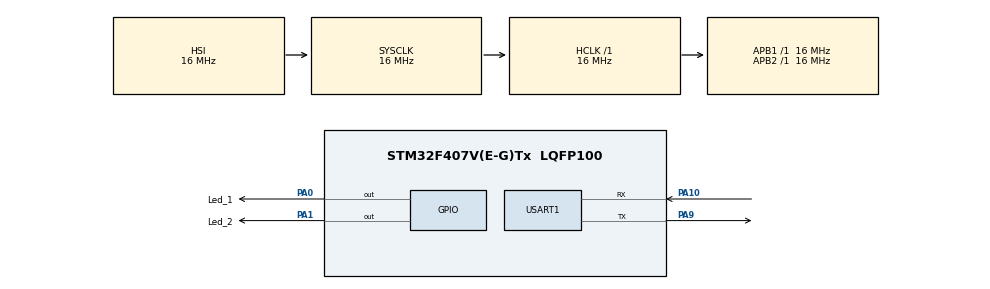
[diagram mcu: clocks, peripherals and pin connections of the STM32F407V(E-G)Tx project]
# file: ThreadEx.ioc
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FREERTOS.Tasks01=Islem1,24,128,Fonksiyon1,Default,NULL,Dynamic,NULL,NULL;Islem2,16,128,Fonksiyon2,Default,NULL,Dynamic,NULL,NULL
Mcu.Family=STM32F4
Mcu.Name=STM32F407V(E-G)Tx
Mcu.Package=LQFP100
NVIC.PriorityGroup=NVIC_PRIORITYGROUP_4
NVIC.TIM1_UP_TIM10_IRQn=true\:15\:0\:false\:false\:true\:false\:false\:true
NVIC.TimeBase=TIM1_UP_TIM10_IRQn
NVIC.TimeBaseIP=TIM1
PA0-WKUP.GPIO_Label=Led_1
PA0-WKUP.Signal=GPIO_Output
PA1.GPIO_Label=Led_2
PA1.Signal=GPIO_Output
PA10.Mode=Asynchronous
PA10.Signal=USART1_RX
PA9.Mode=Asynchronous
PA9.Signal=USART1_TX
PH0-OSC_IN.Mode=HSE-External-Oscillator
PH0-OSC_IN.Signal=RCC_OSC_IN
PH1-OSC_OUT.Mode=HSE-External-Oscillator
PH1-OSC_OUT.Signal=RCC_OSC_OUT
ProjectManager.HeapSize=0x200
ProjectManager.StackSize=0x400
ProjectManager.TargetToolchain=STM32CubeIDE
RCC.AHBFreq_Value=16000000
RCC.APB1Freq_Value=16000000
RCC.APB2Freq_Value=16000000
RCC.CortexFreq_Value=16000000
RCC.HSE_VALUE=25000000
RCC.HSI_VALUE=16000000
RCC.LSE_VALUE=32768
RCC.SYSCLKFreq_VALUE=16000000
RCC.VCOOutputFreq_Value=192000000
USART1.VirtualMode=VM_ASYNC
VP_FREERTOS_VS_CMSIS_V2.Mode=CMSIS_V2
VP_SYS_VS_tim1.Mode=TIM1
board=custom

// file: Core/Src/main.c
/* USER CODE BEGIN Header */
/**
  ******************************************************************************
  * @file           : main.c
  * @brief          : Main program body
  ******************************************************************************
  * @attention
  *
  * Copyright (c) 2023 STMicroelectronics.
  * All rights reserved.
  *
  * This software is licensed under terms that can be found in the LICENSE file
  * in the root directory of this software component.
  * If no LICENSE file comes with this software, it is provided AS-IS.
  *
  ******************************************************************************
  */
/* USER CODE END Header */
#include "main.h"
#include "cmsis_os.h"

UART_HandleTypeDef huart1;

/* Definitions for Islem1 */
osThreadId_t Islem1Handle;
const osThreadAttr_t Islem1_attributes = {
  .name = "Islem1",
  .stack_size = 128 * 4,
  .priority = (osPriority_t) osPriorityNormal,
};
/* Definitions for Islem2 */
osThreadId_t Islem2Handle;
const osThreadAttr_t Islem2_attributes = {
  .name = "Islem2",
  .stack_size = 128 * 4,
  .priority = (osPriority_t) osPriorityBelowNormal,
};

void SystemClock_Config(void);
static void MX_GPIO_Init(void);
static void MX_USART1_UART_Init(void);
void Fonksiyon1(void *argument);
void Fonksiyon2(void *argument);

int main(void)
{

  /* MCU Configuration--------------------------------------------------------*/

  /* Reset of all peripherals, Initializes the Flash interface and the Systick. */
  HAL_Init();

  /* Configure the system clock */
  SystemClock_Config();

  /* Initialize all configured peripherals */
  MX_GPIO_Init();
  MX_USART1_UART_Init();

  /* Init scheduler */
  osKernelInitialize();

  /* Create the thread(s) */
  /* creation of Islem1 */
  Islem1Handle = osThreadNew(Fonksiyon1, NULL, &Islem1_attributes);

  /* creation of Islem2 */
  Islem2Handle = osThreadNew(Fonksiyon2, NULL, &Islem2_attributes);

  /* Start scheduler */
  osKernelStart();

  /* We should never get here as control is now taken by the scheduler */
  /* Infinite loop */
  while (1)
  {

  }
}

void SystemClock_Config(void)
{
  RCC_OscInitTypeDef RCC_OscInitStruct = {0};
  RCC_ClkInitTypeDef RCC_ClkInitStruct = {0};

  /** Configure the main internal regulator output voltage
  */
  __HAL_RCC_PWR_CLK_ENABLE();
  __HAL_PWR_VOLTAGESCALING_CONFIG(PWR_REGULATOR_VOLTAGE_SCALE1);
  /** Initializes the RCC Oscillators according to the specified parameters
  * in the RCC_OscInitTypeDef structure.
  */
  RCC_OscInitStruct.OscillatorType = RCC_OSCILLATORTYPE_HSI;
  RCC_OscInitStruct.HSIState = RCC_HSI_ON;
  RCC_OscInitStruct.HSICalibrationValue = RCC_HSICALIBRATION_DEFAULT;
  RCC_OscInitStruct.PLL.PLLState = RCC_PLL_NONE;
  if (HAL_RCC_OscConfig(&RCC_OscInitStruct) != HAL_OK)
  {
    Error_Handler();
  }
  /** Initializes the CPU, AHB and APB buses clocks
  */
  RCC_ClkInitStruct.ClockType = RCC_CLOCKTYPE_HCLK|RCC_CLOCKTYPE_SYSCLK
                              |RCC_CLOCKTYPE_PCLK1|RCC_CLOCKTYPE_PCLK2;
  RCC_ClkInitStruct.SYSCLKSource = RCC_SYSCLKSOURCE_HSI;
  RCC_ClkInitStruct.AHBCLKDivider = RCC_SYSCLK_DIV1;
  RCC_ClkInitStruct.APB1CLKDivider = RCC_HCLK_DIV1;
  RCC_ClkInitStruct.APB2CLKDivider = RCC_HCLK_DIV1;

  if (HAL_RCC_ClockConfig(&RCC_ClkInitStruct, FLASH_LATENCY_0) != HAL_OK)
  {
    Error_Handler();
  }
}

static void MX_USART1_UART_Init(void)
{

  huart1.Instance = USART1;
  huart1.Init.BaudRate = 115200;
  huart1.Init.WordLength = UART_WORDLENGTH_8B;
  huart1.Init.StopBits = UART_STOPBITS_1;
  huart1.Init.Parity = UART_PARITY_NONE;
  huart1.Init.Mode = UART_MODE_TX_RX;
  huart1.Init.HwFlowCtl = UART_HWCONTROL_NONE;
  huart1.Init.OverSampling = UART_OVERSAMPLING_16;
  if (HAL_UART_Init(&huart1) != HAL_OK)
  {
    Error_Handler();
  }

}

static void MX_GPIO_Init(void)
{
  GPIO_InitTypeDef GPIO_InitStruct = {0};

  /* GPIO Ports Clock Enable */
  __HAL_RCC_GPIOH_CLK_ENABLE();
  __HAL_RCC_GPIOA_CLK_ENABLE();

  /*Configure GPIO pin Output Level */
  HAL_GPIO_WritePin(GPIOA, Led_1_Pin|Led_2_Pin, GPIO_PIN_RESET);

  /*Configure GPIO pins : Led_1_Pin Led_2_Pin */
  GPIO_InitStruct.Pin = Led_1_Pin|Led_2_Pin;
  GPIO_InitStruct.Mode = GPIO_MODE_OUTPUT_PP;
  GPIO_InitStruct.Pull = GPIO_NOPULL;
  GPIO_InitStruct.Speed = GPIO_SPEED_FREQ_LOW;
  HAL_GPIO_Init(GPIOA, &GPIO_InitStruct);

}

void Fonksiyon1(void *argument)
{
  /* USER CODE BEGIN 5 */
  /* Infinite loop */
  for(;;)
  {
	  HAL_GPIO_TogglePin(Led_1_GPIO_Port, Led_1_Pin);
      osDelay(1);
  }
  /* USER CODE END 5 */
}

void Fonksiyon2(void *argument)
{
  /* USER CODE BEGIN Fonksiyon2 */
  /* Infinite loop */
  for(;;)
  {
	  HAL_GPIO_TogglePin(Led_1_GPIO_Port, Led_1_Pin);
      osDelay(1);
  }
  /* USER CODE END Fonksiyon2 */
}

void HAL_TIM_PeriodElapsedCallback(TIM_HandleTypeDef *htim)
{
  if (htim->Instance == TIM1) {
    HAL_IncTick();
  }
}

void Error_Handler(void)
{
  __disable_irq();
  while (1)
  {
  }
}
